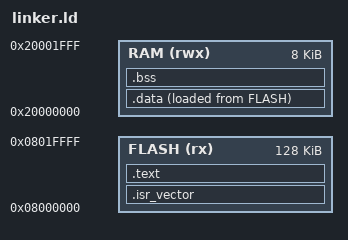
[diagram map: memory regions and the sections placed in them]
ENTRY(Reset_Handler)

MEMORY
{
    FLASH (rx)  : ORIGIN = 0x08000000, LENGTH = 128K
    RAM   (rwx) : ORIGIN = 0x20000000, LENGTH = 8K
}

_stack_top = ORIGIN(RAM) + LENGTH(RAM);

SECTIONS
{
    .isr_vector :
    {
        KEEP(*(.isr_vector))
    } > FLASH

    .text :
    {
        *(.text.Reset_Handler)
        *(.text*)
        *(.rodata*)
    } > FLASH

    .data :
    {
        . = ALIGN(4);
        _data_start = .;

        *(.data*)

        . = ALIGN(4);
        _data_end = .;
    } > RAM AT > FLASH

    _data_load = LOADADDR(.data);

    .bss :
    {
        . = ALIGN(4);
        _bss_start = .;

        *(.bss*)
        *(COMMON)

        . = ALIGN(4);
        _bss_end = .;
    } > RAM
}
